# T113-S3 register map
Vendor: Allwinner; Series: T113-S3; File version: 0.1
CPU: other 0, little endian, MPU, no FPU, 0 interrupt priority bits
Registers are 32-bit, read-write, reset 0x0 unless marked. A register's access mark holds for its fields unless they carry their own. Offsets are from the block's base; [hi:lo] are bit positions; {n}, {i} and the like mark numbered series.

## LEDC
Base 0x02008000
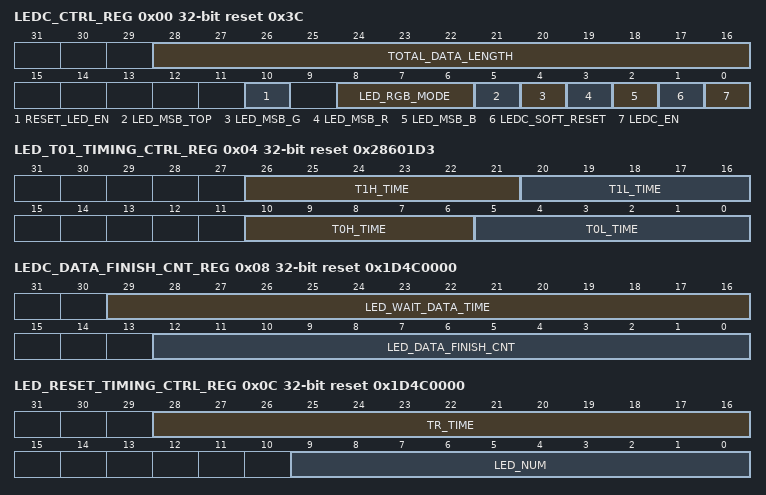
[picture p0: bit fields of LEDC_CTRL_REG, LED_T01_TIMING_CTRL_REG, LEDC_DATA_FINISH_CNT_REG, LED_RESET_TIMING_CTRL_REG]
0x00 LEDC_CTRL_REG reset 0x3C — LEDC Control Register
  [28:16] TOTAL_DATA_LENGTH — Total length of transfer data (range: 0 to 8K, unit: 32-bit, only low 24-bit is valid) The field is recommended to be set to an integer multiple of (LED_NUM+1). If TOTAL_DATA_LENGTH is greater than (LED_NUM+1), but non- integer multiple, the last frame of data will transfer data less than (LED_NUM+1).
  [10] RESET_LED_EN — Write operation: The software writes 1 to the bit, the CPU triggers LEDC to transfer a reset to LED. Only when LEDC is in IDLE status, the reset can be performed. After the reset finished, the control state machine returns to the IDLE status. To return LEDC to the IDLE status, it also needs to be used with SOFT_RESET. When the software sets the bit, the software can read the bit to check if the reset is complete. Read operation: 0: LEDC completes the transmission of the LED reset operation 1: LEDC does not complete the transmission of the LED reset operation
    0=LEDC completes the transmission of the LED reset operation; 1=LEDC does not complete the transmission of the LED reset operation
  [8:6] LED_RGB_MODE — 000 GRB (bypass) 001 GBR 010 RGB 011 RBG 100 BGR 101 BRG By default, the software configures data to LEDC according to GRB (MSB) mode, the LEDC internal combines data to output to the external LED. Other modes configure as follows. Software Input Mode Configuration LEDC Output Mode GRB 000 GRB 001 GBR 010 RGB 011 RBG 100 BGR 101 BRG GBR 000 GBR 001 GRB 010 BGR 011 BRG 100 RGB 101 RBG RGB 000 RGB 001 RBG 010 GRB 011 GBR 100 BRG 101 BGR RBG 000 RBG 001 RGB 010 BRG 011 BGR 100 GRB 101 GBR BGR 000 BGR 001 BRG 010 GBR 011 GRB 100 RBG 101 RGB BRG 000 BRG 001 BGR 010 RBG 011 RGB 100 GBR 101 GRB
  [5] LED_MSB_TOP — Adjust sequence of the combined GRB data 0: LSB 1: MSB
    0=LSB; 1=MSB
  [4] LED_MSB_G — MSB control for Green data 0: LSB 1: MSB
    0=LSB; 1=MSB
  [3] LED_MSB_R — MSB control for Red data 0: LSB 1: MSB
    0=LSB; 1=MSB
  [2] LED_MSB_B — MSB control for Blue data 0: LSB 1: MSB
    0=LSB; 1=MSB
  [1] LEDC_SOFT_RESET write-1-clears — LEDC soft reset Write 1 to clear it automatically. The ranges of LEDC soft reset include the following points: all internal status registers, the control state machine returns to in idle status, the LEDC FIFO read & write point is cleared to 0, the LEDC interrupt is cleared; and the affected registers are followed. 1.LEDC_CTRL_REG (LEDC_EN is cleared to 0); 2. PLL_T0&1_TIMING_CTRL_REG remains unchanged; 3. LEDC_DATA_FINISH_CNT_REG (LEDC_DATA_FINISH_CNT is cleared to 0); 4.LED_RESET_TIMING_CTRL_REG remains unchanged; 5. LEDC_WAIT_TIME_CTRL_REG remains unchanged; 6. LEDC_DMA_CTRL_REG remains unchanged; 7. LEDC_INTERRUPT_CTRL_REG remains unchanged; 8.LEDC_INT_STS _REG is cleared to 0; 9. LEDC_CLK_GATING_REG remains unchanged; 10.LEDC_FIFO_DATA_REG remains unchanged;
  [0] LEDC_EN — LEDC Enable 0: Disable 1: Enable That the bit is enabled indicates LEDC can be started when LEDC data finished transmission or LEDC_EN is cleared to 0 by hardware in LEDC_SOFT_RESET situation.
    0=Disable; 1=Enable That the bit is enabled indicates LEDC can be started when LEDC data finished transmission or LEDC_EN is cleared to 0 by hardware in LEDC_SOFT_RESET situation
0x04 LED_T01_TIMING_CTRL_REG reset 0x28601D3 — LEDC T0 & T1 Timing Control Register
  [26:21] T1H_TIME — LED T1H time Unit: cycle (24 MHz), T1H_TIME =42 ns*(N+1) The default value is 882 ns, the range is 80 ns-2560 ns. N: 1-3F. When is 0, T1H_TIME = 3F
  [20:16] T1L_TIME — LED T1L time Unit: cycle (24 MHz), T1L_TIME =42 ns*(N+1) The default value is 294 ns, the range is 80 ns-1280 ns. N: 1-1F. When is 0, T1L_TIME = 1F
  [10:6] T0H_TIME — LED T0h time Unit: cycle (24 MHz), T0H_TIME =42 ns*(N+1) The default value is 336 ns, the range is 80 ns-1280 ns. N: 1-1F. When is 0, T0H_TIME = 1F
  [5:0] T0L_TIME — LED T0l time Unit: cycle (24 MHz), T0L_TIME =42 ns*(N+1) The default value is 840 ns, the range is 80 ns-2560 ns. N: 1-3F. When is 0, T0L_TIME = 3F
0x08 LEDC_DATA_FINISH_CNT_REG reset 0x1D4C0000 — LEDC Data Finish Counter Register
  [29:16] LED_WAIT_DATA_TIME — The value is the time that internal FIFO in LEDC is waiting for data. When the time is exceeded, the LEDC will send the wait_data_timeout_int interrupt. (This is an abnormal situation, software needs to reset LEDC.) The value is about 300 us by default. The adjust range is 80 ns-655 us. led_wait_data_time=42ns*(N+1). N: 1-1FFF. When the field is 0, LEDC_WAIT_DATA_TIME=1FFF
  [12:0] LED_DATA_FINISH_CNT ro — The value is the total LED data that have been sent. (Range: 0- 8k)
0x0C LED_RESET_TIMING_CTRL_REG reset 0x1D4C0000 — LEDC Reset Timing Control Register
  [28:16] TR_TIME — Reset time control of LED lamp Unit: cycle (24 MHz), tr_time=42 ns*(N+1) The default value is 300 us. The adjust range is 80 ns-327 us. N: 1-1FFF
  [9:0] LED_NUM — The value is the number of external LED lamp. Maximum up to 1024. The default value 0 indicates that 1 LED lamp is external connected. The range is from 0 to 1023.
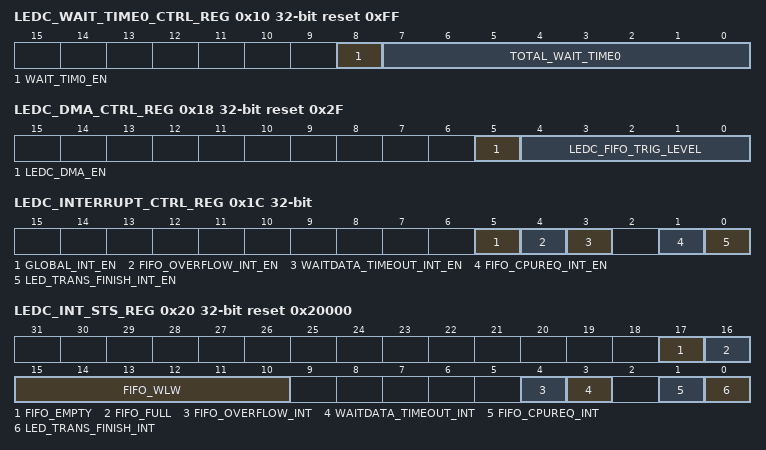
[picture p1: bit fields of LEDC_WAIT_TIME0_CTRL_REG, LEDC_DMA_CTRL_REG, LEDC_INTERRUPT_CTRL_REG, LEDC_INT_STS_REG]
0x10 LEDC_WAIT_TIME0_CTRL_REG reset 0xFF — LEDC Wait Time0 Control Register
  [8] WAIT_TIM0_EN — WAIT_TIME0 enable When it is 1, the controller automatically inserts waiting time between LED package data. 0: Disable 1: Enable
    0=Disable; 1=Enable
  [7:0] TOTAL_WAIT_TIME0 — Waiting time between 2 LED data. The LEDC output is low level. The adjust range is 80 ns-10 us. wait_time0=42 ns*(N+1) Unit: cycle(24 MHz) N: 1-FF
0x14 LEDC_DATA_REG — LEDC Data Register
  [31:0] LEDC wo — DATA LED display data (the lower 24-bit is valid)
0x18 LEDC_DMA_CTRL_REG reset 0x2F — LEDC DMA Control Register
  [5] LEDC_DMA_EN — LEDC DMA request enable 0: Disable request of DMA transfer data 1: Enable request of DMA transfer data
    0=Disable request of DMA transfer data; 1=Enable request of DMA transfer data
  [4:0] LEDC_FIFO_TRIG_LEVEL — The remaining space of internal FIFO in LEDC The internal FIFO in LEDC is 24*32. When the remaining space of internal FIFO in LEDC is more than or equal to LEDFIFO_TRIG_LEVEL, the DMA or the CPU request will generate. The default value is 15. The adjusted value is from 1 to 31. The recommended configuration is 7 or 15. When the configuration value is 0, LEDFIFO_TRIG_LEVEL=F.
0x1C LEDC_INTERRUPT_CTRL_REG
  [all] fields
    0=Disable; 1=Enable
  [5] GLOBAL_INT_EN — Global interrupt enable 0: Disable 1: Enable
  [4] FIFO_OVERFLOW_INT_EN — FIFO overflow interrupt enable When the data written by the software is more than the internal FIFO level of LEDC, the LEDC is in the data loss state. 0: Disable 1: Enable
  [3] WAITDATA_TIMEOUT_INT_EN — The internal FIFO in LEDC cannot get data because of some abnormal situation, after the time of led_wait_data_time, the interrupt will be enabled. 0: Disable 1: Enable
  [1] FIFO_CPUREQ_INT_EN — FIFO request CPU data interrupt enable 0: Disable 1: Enable
  [0] LED_TRANS_FINISH_INT_EN — Data transmission complete interrupt enable 0: Disable 1: Enable
0x20 LEDC_INT_STS_REG reset 0x20000 — LEDC Interrupt Status Register
  [17] FIFO_EMPTY ro — FIFO empty status flag
  [16] FIFO_FULL ro — FIFO full status flag
  [15:10] FIFO_WLW ro — FIFO internal valid data depth It indicates the space FIFO has been occupied.
  [4] FIFO_OVERFLOW_INT write-1-clears — FIFO overflow interrupt The data written by external is more than the maximum storage space of LED FIFO, the LEDC will be in the data loss state. At this time, the software needs to deal with the abnormal situation. The processing mode is as follows. (1) The software can query LED_FIFO_DATA_REG to determine which data has been stored in the internal FIFO of LEDC. (2) The LEDC performs soft_reset operation to refresh all data. 0: FIFO not overflow 1: FIFO overflow
    0=FIFO_not_overflow; 1=FIFO_overflow
  [3] WAITDATA_TIMEOUT_INT write-1-clears — When internal FIFO of LEDC cannot get data because of some abnormal situation, after led_wait_data_time, the timeout interrupt is set, the LEDC is in WAIT_DATA state, the LEDC outputs a level state configured by LED_POLARITY; in the course of wait_data, if the new data arrives, the LEDC will continue to send data, at this time software needs to notice whether the waiting time of LEDC exceeds the operation time of reset. If the waiting time of LEDC exceeds the operation time of reset (this is equivalent to reset operation sent by LEDC), the LED may enter in refresh state, the data has not been sent. 0: LEDC not timeout 1: LEDC timeout
    0=LEDC (LEDC not timeout); 1=LEDC_timeout
  [1] FIFO_CPUREQ_INT write-1-clears — FIFO request CPU data interrupt When FIFO data is less than the threshold, the interrupt will be reported to the CPU. 0: FIFO does not request that CPU transfers data 1: FIFO requests that CPU transfers data
    0=FIFO does not request that CPU transfers data; 1=FIFO requests that CPU transfers data
  [0] LED_TRANS_FINISH_INT write-1-clears — Data transfer complete interrupt The value indicates that the data configured as total_data_length is transferred completely. 0: Data is not transferred completely 1: Data is transferred completely
    0=not_transferred (Data is not transferred completely); 1=transferred (Data is transferred completely)
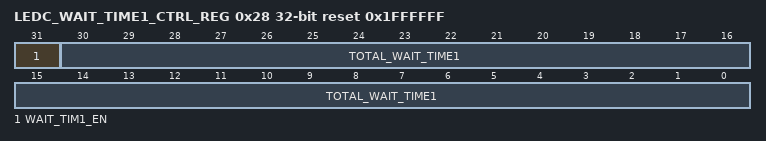
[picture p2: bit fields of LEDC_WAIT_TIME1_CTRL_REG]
0x28 LEDC_WAIT_TIME1_CTRL_REG reset 0x1FFFFFF — LEDC Wait Time1 Control Register
  [31] WAIT_TIM1_EN — 0: Disable 1: Enable WAIT_TIME1 enable When the bit is 1, the controller automatically inserts the waiting time between the LED frame data.
    0=Disable; 1=Enable WAIT_TIME1 enable When the bit is 1, the controller automatically inserts the waiting time between the LED frame data
  [30:0] TOTAL_WAIT_TIME1 — Waiting time between 2 frame data. The LEDC output is low level. The adjust range is 80 ns- 85 s. wait_time1=42 ns*(N+1) Unit: cycle (24 MHz) N: 0x80-0x7FFFFFFF If the value is 0, TOTAL_WAIT_TIME1=0x7FFFFFFF
{0x30+4i} LEDC_FIFO_DATA_X[{i}] (i=0..31) — LEDC_FIFO_DATA_X[{i}]
  [31:0] LEDC_FIFO_DATA_X ro — Internal FIFO data of LEDC The lower 24-bit is valid.
